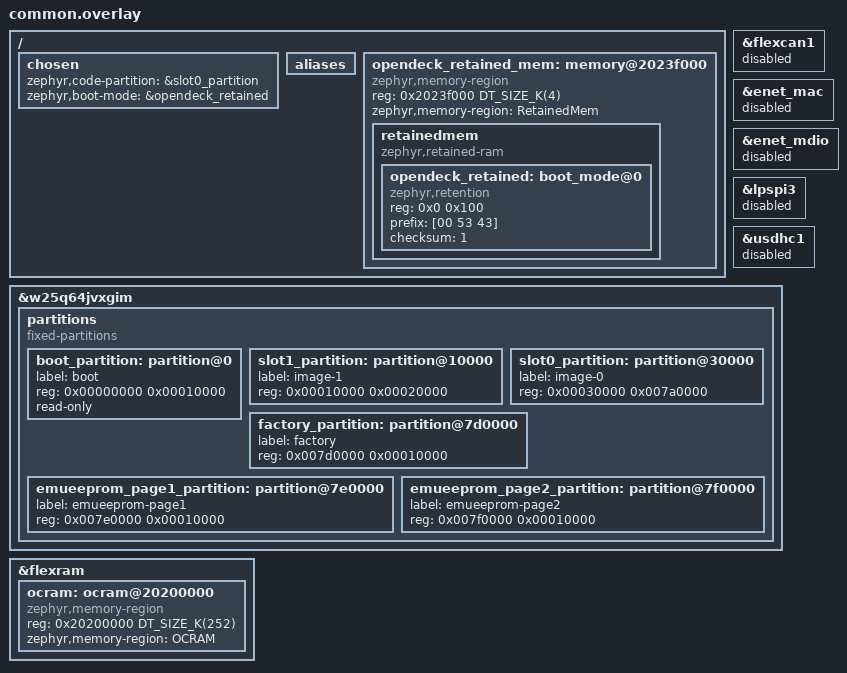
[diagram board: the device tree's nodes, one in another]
/ {
    chosen {
        /delete-property/ zephyr,canbus;
    };

    aliases {
        /delete-property/ led0;
    };

    /delete-node/ leds;
};

&flexcan1 {
    status = "disabled";
};

&enet_mac {
    status = "disabled";
};

&enet_mdio {
    status = "disabled";
};

&lpspi3 {
    status = "disabled";
};

&usdhc1 {
    status = "disabled";
};

&w25q64jvxgim {
    partitions {
        compatible = "fixed-partitions";
        #address-cells = <1>;
        #size-cells = <1>;

        boot_partition: partition@0 {
            label = "boot";
            reg = <0x00000000 0x00010000>;
            read-only;
        };

        /* image-1 is the OpenDeck bootloader; keep it before image-0 so merged images stay compact. */
        slot1_partition: partition@10000 {
            label = "image-1";
            reg = <0x00010000 0x00020000>;
        };

        slot0_partition: partition@30000 {
            label = "image-0";
            reg = <0x00030000 0x007a0000>;
        };

        factory_partition: partition@7d0000 {
            label = "factory";
            reg = <0x007d0000 0x00010000>;
        };

        emueeprom_page1_partition: partition@7e0000 {
            label = "emueeprom-page1";
            reg = <0x007e0000 0x00010000>;
        };

        emueeprom_page2_partition: partition@7f0000 {
            label = "emueeprom-page2";
            reg = <0x007f0000 0x00010000>;
        };
    };
};

&flexram {
    /delete-node/ ocram@20280000;

    ocram: ocram@20200000 {
        compatible = "zephyr,memory-region", "mmio-sram";
        reg = <0x20200000 DT_SIZE_K(252)>;
        zephyr,memory-region = "OCRAM";
    };
};

/ {
    chosen {
        zephyr,code-partition = &slot0_partition;
        zephyr,boot-mode = &opendeck_retained;
    };

    opendeck_retained_mem: memory@2023f000 {
        compatible = "zephyr,memory-region", "mmio-sram";
        reg = <0x2023f000 DT_SIZE_K(4)>;
        zephyr,memory-region = "RetainedMem";
        status = "okay";

        retainedmem {
            compatible = "zephyr,retained-ram";
            status = "okay";
            #address-cells = <1>;
            #size-cells = <1>;

            opendeck_retained: boot_mode@0 {
                compatible = "zephyr,retention";
                status = "okay";
                reg = <0x0 0x100>;
                prefix = [00 53 43];
                checksum = <1>;
            };
        };
    };
};
